VERSION "Nissan Leaf 2025 capstone DBC - original names plus verified gear observations"

NS_ :

BS_:
BU_: XXX

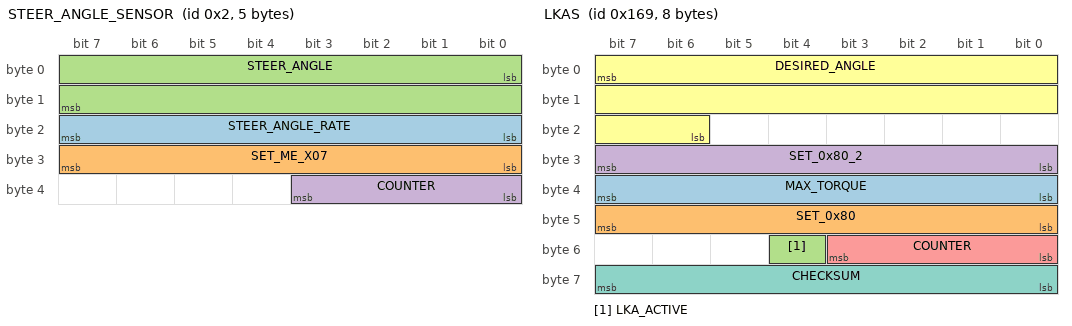
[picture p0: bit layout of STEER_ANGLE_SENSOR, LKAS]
BO_ 2 STEER_ANGLE_SENSOR: 5 XXX
 SG_ STEER_ANGLE_RATE : 16|8@1+ (1,0) [0|255] "" XXX
 SG_ SET_ME_X07 : 24|8@1+ (1,0) [0|255] "" XXX
 SG_ STEER_ANGLE : 0|16@1- (-0.1,0) [-3276.7|3276.8] "deg" XXX
 SG_ COUNTER : 32|4@1+ (1,0) [0|15] "" XXX

BO_ 42 SEATBELT: 8 XXX
 SG_ SEATBELT_DRIVER_LATCHED : 27|1@1+ (1,0) [0|1] "" XXX
 SG_ SEATBELT_DRIVER_UNLATCHED : 26|1@0+ (1,0) [0|1] "" XXX

BO_ 361 LKAS: 8 XXX
 SG_ MAX_TORQUE : 39|8@0+ (0.01,0) [0|2.55] "Nm" XXX
 SG_ SET_0x80 : 47|8@0+ (1,0) [0|255] "" XXX
 SG_ LKA_ACTIVE : 52|1@0+ (1,0) [0|1] "" XXX
 SG_ SET_0x80_2 : 31|8@0+ (1,0) [0|255] "" XXX
 SG_ COUNTER : 51|4@0+ (1,0) [0|15] "" XXX
 SG_ DESIRED_ANGLE : 7|18@0+ (-0.01,1310) [-1311.43|1310] "deg" XXX
 SG_ CHECKSUM : 63|8@0+ (1,0) [0|255] "" XXX

BO_ 372 GEAR_POSITION_STATUS: 8 XXX
 SG_ GEAR_POSITION : 24|8@1+ (1,0) [0|255] "" XXX
 SG_ GEAR_COUNTER : 32|4@1+ (1,0) [0|15] "" XXX

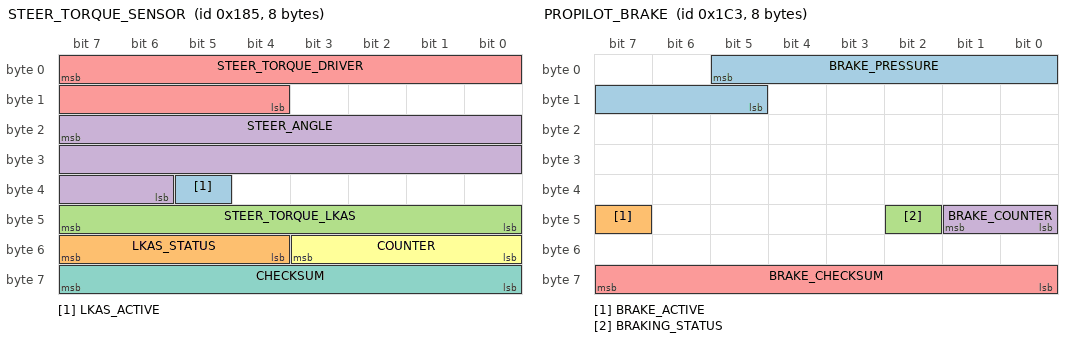
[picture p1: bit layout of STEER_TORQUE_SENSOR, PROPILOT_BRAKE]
BO_ 389 STEER_TORQUE_SENSOR: 8 XXX
 SG_ LKAS_ACTIVE : 37|1@0+ (1,0) [0|1] "" XXX
 SG_ LKAS_STATUS : 55|4@0+ (1,0) [0|15] "" XXX
 SG_ STEER_TORQUE_LKAS : 47|8@0+ (1,0) [0|255] "" XXX
 SG_ STEER_ANGLE : 23|18@0+ (-0.01,1310) [-1311.43|1310] "deg" XXX
 SG_ STEER_TORQUE_DRIVER : 7|12@0+ (-0.01,20.47) [-20.48|20.47] "Nm" XXX
 SG_ COUNTER : 51|4@0+ (1,0) [0|15] "" XXX
 SG_ CHECKSUM : 63|8@0+ (1,0) [0|255] "" XXX

BO_ 451 PROPILOT_BRAKE: 8 XXX
 SG_ BRAKE_PRESSURE : 5|9@0+ (1,0) [0|511] "" XXX
 SG_ BRAKE_ACTIVE : 47|1@0+ (1,0) [0|1] "" XXX
 SG_ BRAKING_STATUS : 42|1@1+ (1,0) [0|1] "" XXX
 SG_ BRAKE_COUNTER : 40|2@1+ (1,0) [0|3] "" XXX
 SG_ BRAKE_CHECKSUM : 56|8@1+ (1,0) [0|255] "" XXX

BO_ 459 BRAKE_RELATED_1CB: 7 XXX
 SG_ BRAKE_RELATED_STATUS : 13|1@1+ (1,0) [0|1] "" XXX
 SG_ BRAKE_RELATED_VALUE : 16|8@1+ (1,0) [0|255] "" XXX

BO_ 460 BRAKE_PEDAL: 4 XXX
 SG_ BRAKE_PEDAL : 7|8@0+ (1,0) [0|255] "" XXX

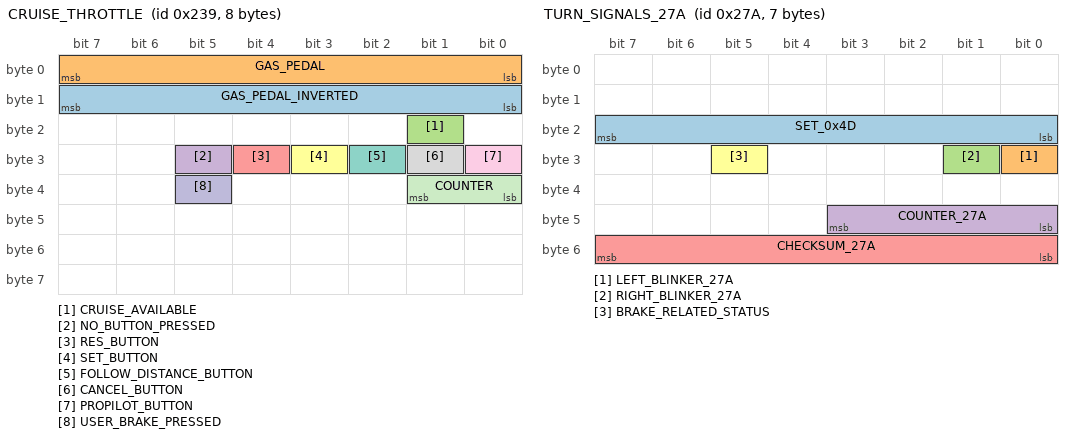
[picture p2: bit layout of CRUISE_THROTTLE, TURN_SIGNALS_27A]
BO_ 569 CRUISE_THROTTLE: 8 XXX
 SG_ GAS_PEDAL_INVERTED : 15|8@0+ (1,0) [0|255] "" XXX
 SG_ GAS_PEDAL : 7|8@0+ (1,0) [0|255] "" XXX
 SG_ CRUISE_AVAILABLE : 17|1@0+ (1,0) [0|1] "" XXX
 SG_ NO_BUTTON_PRESSED : 29|1@0+ (1,0) [0|1] "" XXX
 SG_ RES_BUTTON : 28|1@0+ (1,0) [0|1] "" XXX
 SG_ SET_BUTTON : 27|1@0+ (1,0) [0|1] "" XXX
 SG_ FOLLOW_DISTANCE_BUTTON : 26|1@0+ (1,0) [0|1] "" XXX
 SG_ CANCEL_BUTTON : 25|1@0+ (1,0) [0|1] "" XXX
 SG_ PROPILOT_BUTTON : 24|1@0+ (1,0) [0|1] "" XXX
 SG_ USER_BRAKE_PRESSED : 37|1@0+ (1,0) [0|1] "" XXX
 SG_ COUNTER : 32|2@1+ (1,0) [0|3] "" XXX

BO_ 634 TURN_SIGNALS_27A: 7 XXX
 SG_ SET_0x4D : 23|8@0+ (1,0) [0|255] "" XXX
 SG_ LEFT_BLINKER_27A : 24|1@1+ (1,0) [0|1] "" XXX
 SG_ RIGHT_BLINKER_27A : 25|1@1+ (1,0) [0|1] "" XXX
 SG_ COUNTER_27A : 40|4@1+ (1,0) [0|15] "" XXX
 SG_ CHECKSUM_27A : 48|8@1+ (1,0) [0|255] "" XXX
 SG_ BRAKE_RELATED_STATUS : 29|1@1+ (1,0) [0|1] "" XXX

BO_ 640 CANCEL_MSG: 8 XXX
 SG_ CANCEL_SEATBELT : 1|1@0+ (1,0) [0|1] "" XXX

BO_ 644 WHEEL_SPEEDS_FRONT: 8 XXX
 SG_ WHEEL_SPEED_FR : 7|16@0+ (0.005,0) [0|327.675] "KPH" XXX
 SG_ WHEEL_SPEED_FL : 23|16@0+ (0.005,0) [0|327.675] "KPH" XXX

BO_ 645 WHEEL_SPEEDS_REAR: 8 XXX
 SG_ WHEEL_SPEED_RR : 7|16@0+ (0.005,0) [0|327.675] "KPH" XXX
 SG_ WHEEL_SPEED_RL : 23|16@0+ (0.005,0) [0|327.675] "KPH" XXX

BO_ 654 BRAKE_RELATED_28E: 6 XXX
 SG_ AUTO_BRAKING_STATUS : 16|1@1+ (1,0) [0|1] "" XXX

BO_ 658 ACCEL: 8 XXX
 SG_ ROUGH_ACCEL : 7|16@0+ (0.0005,-16.5) [-16.5|16.27] "m/s^2" XXX

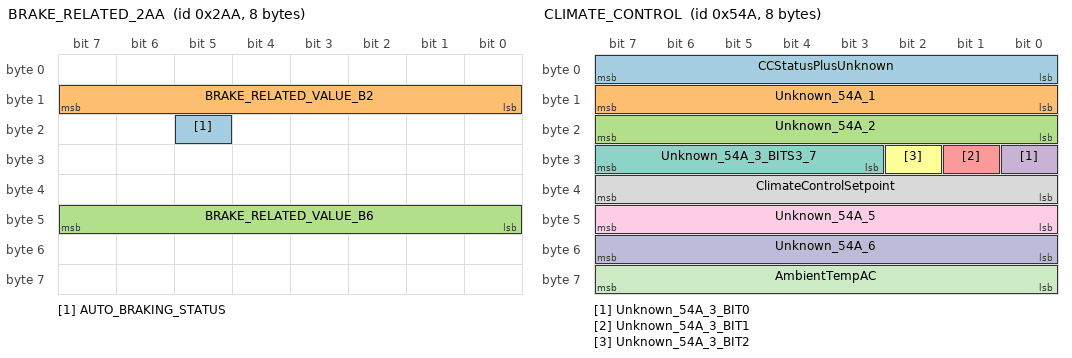
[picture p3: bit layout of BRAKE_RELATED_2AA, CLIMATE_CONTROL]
BO_ 682 BRAKE_RELATED_2AA: 8 XXX
 SG_ AUTO_BRAKING_STATUS : 21|1@1+ (1,0) [0|1] "" XXX
 SG_ BRAKE_RELATED_VALUE_B2 : 8|8@1+ (1,0) [0|255] "" XXX
 SG_ BRAKE_RELATED_VALUE_B6 : 40|8@1+ (1,0) [0|255] "" XXX

BO_ 688 BRAKE_RELATED_2B0: 8 XXX
 SG_ AUTO_BRAKING_STATUS : 22|1@1+ (1,0) [0|1] "" XXX

BO_ 689 PROPILOT_HUD: 8 XXX
 SG_ LARGE_WARNING_FLASHING : 9|1@0+ (1,0) [0|1] "" XXX
 SG_ SIDE_RADAR_ERROR_FLASHING1 : 10|1@0+ (1,0) [0|1] "" XXX
 SG_ SIDE_RADAR_ERROR_FLASHING2 : 11|1@0+ (1,0) [0|1] "" XXX
 SG_ RIGHT_LANE_YELLOW_FLASH : 12|1@0+ (1,0) [0|1] "" XXX
 SG_ LEFT_LANE_YELLOW_FLASH : 13|1@0+ (1,0) [0|1] "" XXX
 SG_ LEAD_CAR : 14|1@0+ (1,0) [0|1] "" XXX
 SG_ LEAD_CAR_ERROR : 15|1@0+ (1,0) [0|1] "" XXX
 SG_ FRONT_RADAR_ERROR : 16|1@0+ (1,0) [0|1] "" XXX
 SG_ FRONT_RADAR_ERROR_FLASHING : 17|1@0+ (1,0) [0|1] "" XXX
 SG_ RIGHT_LANE_GREEN : 24|1@0+ (1,0) [0|1] "" XXX
 SG_ LEFT_LANE_GREEN : 25|1@0+ (1,0) [0|1] "" XXX
 SG_ SIDE_RADAR_ERROR_FLASHING3 : 27|1@0+ (1,0) [0|1] "" XXX
 SG_ LKAS_ERROR_FLASHING : 29|1@0+ (1,0) [0|1] "" XXX
 SG_ SAFETY_SHIELD_ACTIVE : 44|1@0+ (1,0) [0|1] "" XXX
 SG_ LARGE_STEERING_WHEEL_ICON : 61|2@0+ (1,0) [0|3] "" XXX
 SG_ RIGHT_LANE_GREEN_FLASH : 62|1@0+ (1,0) [0|1] "" XXX
 SG_ LEFT_LANE_GREEN_FLASH : 63|1@0+ (1,0) [0|1] "" XXX
 SG_ FOLLOW_DISTANCE : 3|2@0+ (1,0) [0|3] "" XXX
 SG_ AUDIBLE_TONE : 47|3@0+ (1,0) [0|7] "" XXX
 SG_ SPEED_SET_ICON : 7|2@0+ (1,0) [0|3] "" XXX
 SG_ SMALL_STEERING_WHEEL_ICON : 42|3@0+ (1,0) [0|7] "" XXX
 SG_ SET_SPEED : 39|8@0+ (1,0) [0|255] "" XXX

BO_ 761 BRAKE_RELATED_2F9: 2 XXX
 SG_ AUTO_BRAKING_STATUS_INVERTED : 6|1@1+ (1,0) [0|1] "" XXX

BO_ 783 CRUISE_STATE: 3 XXX
 SG_ CRUISE_ENABLED : 3|1@0+ (1,0) [0|1] "" XXX

BO_ 852 ESP: 8 XXX
 SG_ ESP_DISABLED : 38|1@0+ (1,0) [0|1] "" XXX
 SG_ BRAKE_RELATED_STATUS : 52|1@1+ (1,0) [0|1] "" XXX

BO_ 853 HUD_SETTINGS: 8 XXX
 SG_ SPEED_MPH : 37|1@0+ (1,0) [0|1] "" XXX

BO_ 856 LIGHTS: 8 XXX
 SG_ LEFT_BLINKER : 17|1@0+ (1,0) [0|1] "" XXX
 SG_ RIGHT_BLINKER : 18|1@0+ (1,0) [0|1] "" XXX

BO_ 861 BRAKE_RELATED_35D: 8 XXX
 SG_ BRAKE_RELATED_STATUS : 36|1@1+ (1,0) [0|1] "" XXX

BO_ 943 HAZARD_SWITCH: 8 XXX
 SG_ HAZARD_BUTTON : 7|1@1+ (1,0) [0|1] "" XXX

BO_ 976 GEAR_SYSTEM_STATUS: 6 XXX
 SG_ GEAR_STATE : 8|8@1+ (1,0) [0|255] "" XXX
 SG_ GEAR_COUNTER : 40|2@1+ (1,0) [0|3] "" XXX

BO_ 1057 GEARBOX: 3 XXX
 SG_ GEAR_SHIFTER : 5|3@0+ (1,0) [0|7] "" XXX

BO_ 1227 LKAS_SETTINGS: 8 XXX
 SG_ LKAS_ENABLED : 51|1@0+ (1,0) [0|1] "" XXX

BO_ 1228 PROPILOT_HUD_INFO_MSG: 8 XXX
 SG_ NA_HIGH_ACCEL_TEMP : 0|1@0+ (1,0) [0|1] "" XXX
 SG_ SIDE_RADAR_NA_HIGH_CABIN_TEMP : 8|1@0+ (1,0) [0|1] "" XXX
 SG_ SIDE_RADAR_MALFUNCTION : 11|1@0+ (1,0) [0|1] "" XXX
 SG_ LKAS_MALFUNCTION : 12|1@0+ (1,0) [0|1] "" XXX
 SG_ FRONT_RADAR_MALFUNCTION : 13|1@0+ (1,0) [0|1] "" XXX
 SG_ SIDE_RADAR_NA_CLEAN_REAR_CAMERA : 14|1@0+ (1,0) [0|1] "" XXX
 SG_ NA_POOR_ROAD_CONDITIONS : 16|1@0+ (1,0) [0|1] "" XXX
 SG_ CURRENTLY_UNAVAILABLE : 17|1@0+ (1,0) [0|1] "" XXX
 SG_ SAFETY_SHIELD_OFF : 18|1@0+ (1,0) [0|1] "" XXX
 SG_ FRONT_COLLISION_NA_FRONT_RADAR_OBSTRUCTION : 20|1@0+ (1,0) [0|1] "" XXX
 SG_ PEDAL_MISSAPPLICATION_SYSTEM_ACTIVATED : 24|1@0+ (1,0) [0|1] "" XXX
 SG_ SIDE_IMPACT_NA_RADAR_OBSTRUCTION : 25|1@0+ (1,0) [0|1] "" XXX
 SG_ WARNING_DO_NOT_ENTER : 33|1@0+ (1,0) [0|1] "" XXX
 SG_ SIDE_IMPACT_SYSTEM_OFF : 34|1@0+ (1,0) [0|1] "" XXX
 SG_ SIDE_IMPACT_MALFUNCTION : 35|1@0+ (1,0) [0|1] "" XXX
 SG_ FRONT_COLLISION_MALFUNCTION : 36|1@0+ (1,0) [0|1] "" XXX
 SG_ SIDE_RADAR_MALFUNCTION2 : 37|1@0+ (1,0) [0|1] "" XXX
 SG_ LKAS_MALFUNCTION2 : 38|1@0+ (1,0) [0|1] "" XXX
 SG_ FRONT_RADAR_MALFUNCTION2 : 39|1@0+ (1,0) [0|1] "" XXX
 SG_ PROPILOT_NA_MSGS : 42|3@0+ (1,0) [0|7] "" XXX
 SG_ BOTTOM_MSG : 45|3@0+ (1,0) [0|7] "" XXX
 SG_ HANDS_ON_WHEEL_WARNING : 47|1@0+ (1,0) [0|1] "" XXX
 SG_ WARNING_STEP_ON_BRAKE_NOW : 51|1@0+ (1,0) [0|1] "" XXX
 SG_ PROPILOT_NA_FRONT_CAMERA_OBSTRUCTED : 52|1@0+ (1,0) [0|1] "" XXX
 SG_ PROPILOT_NA_HIGH_CABIN_TEMP : 53|1@0+ (1,0) [0|1] "" XXX
 SG_ WARNING_PROPILOT_MALFUNCTION : 54|1@0+ (1,0) [0|1] "" XXX
 SG_ ACC_UNAVAILABLE_HIGH_CABIN_TEMP : 62|1@0+ (1,0) [0|1] "" XXX
 SG_ ACC_NA_FRONT_CAMERA_IMPARED : 63|1@0+ (1,0) [0|1] "" XXX

BO_ 1354 CLIMATE_CONTROL: 8 XXX
 SG_ CCStatusPlusUnknown : 0|8@1+ (1,0) [0|255] "" XXX
 SG_ Unknown_54A_1 : 8|8@1+ (1,0) [0|255] "" XXX
 SG_ Unknown_54A_2 : 16|8@1+ (1,0) [0|255] "" XXX
 SG_ Unknown_54A_3_BIT0 : 24|1@1+ (1,0) [0|1] "" XXX
 SG_ Unknown_54A_3_BIT1 : 25|1@1+ (1,0) [0|1] "" XXX
 SG_ Unknown_54A_3_BIT2 : 26|1@1+ (1,0) [0|1] "" XXX
 SG_ Unknown_54A_3_BITS3_7 : 27|5@1+ (1,0) [0|31] "" XXX
 SG_ ClimateControlSetpoint : 32|8@1+ (1,0) [0|255] "" XXX
 SG_ Unknown_54A_5 : 40|8@1+ (1,0) [0|255] "" XXX
 SG_ Unknown_54A_6 : 48|8@1+ (1,0) [0|255] "" XXX
 SG_ AmbientTempAC : 56|8@1+ (1,0) [0|255] "" XXX

BO_ 1402 REVERSE_STATUS: 8 XXX
 SG_ REVERSE_RELATED_STATE : 0|8@1+ (1,0) [0|255] "" XXX

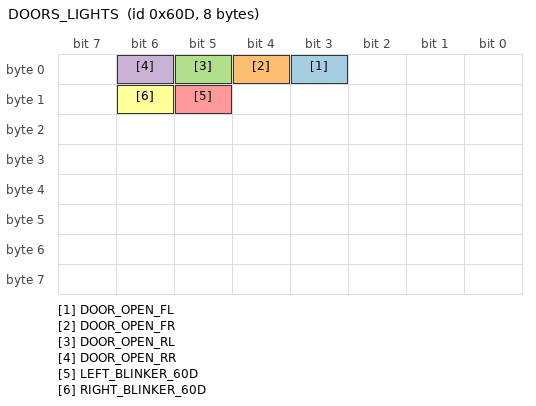
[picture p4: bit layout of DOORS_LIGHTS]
BO_ 1549 DOORS_LIGHTS: 8 XXX
 SG_ DOOR_OPEN_FL : 3|1@0+ (1,0) [0|1] "" XXX
 SG_ DOOR_OPEN_FR : 4|1@0+ (1,0) [0|1] "" XXX
 SG_ DOOR_OPEN_RL : 5|1@0+ (1,0) [0|1] "" XXX
 SG_ DOOR_OPEN_RR : 6|1@0+ (1,0) [0|1] "" XXX
 SG_ LEFT_BLINKER_60D : 13|1@1+ (1,0) [0|1] "" XXX
 SG_ RIGHT_BLINKER_60D : 14|1@1+ (1,0) [0|1] "" XXX

CM_ SG_ 389 LKAS_STATUS "EPS LKAS state.";
VAL_ 389 LKAS_STATUS 5 "INACTIVE" 6 "ACTIVE" 9 "FAULT" ;
VAL_ 1057 GEAR_SHIFTER 7 "B" 4 "D" 3 "N" 2 "R" 1 "P" ;
VAL_ 1228 PROPILOT_NA_MSGS 0 "NO_MSG" 1 "NA_FRONT_CAMERA_IMPAIRED" 2 "STEERING_ASSIST_ON_STANDBY" 3 "NA_PARKING_ASSIST_ENABLED" 4 "STEER_ASSIST_CURRENTLY_NA" 5 "NA_BAD_WEATHER" 6 "NA_PARK_BRAKE_ON" 7 "NA_SEATBELT_NOT_FASTENED" ;
VAL_ 1228 BOTTOM_MSG 0 "OK_STEER_ASSIST_SETTINGS" 1 "NO_MSG" 2 "PRESS_SET_TO_SET_SPEED" 3 "PRESS_RES_SET_TO_CHANGE_SPEED" 4 "PRESS_RES_TO_RESTART" 5 "NO_MSG" 6 "CRUISE_NOT_AVAIL" 7 "NO_MSG" ;
VAL_ 689 FOLLOW_DISTANCE 0 "NO_FOLLOW_DISTANCE" 1 "FOLLOW_DISTANCE_1" 2 "FOLLOW_DISTANCE_2" 3 "FOLLOW_DISTANCE_3" ;
VAL_ 689 AUDIBLE_TONE 0 "NO_TONE" 1 "CONT" 2 "FAST_BEEP_CONT" 3 "TRIPLE_FAST_BEEP_CONT" 4 "SLOW_BEEP_CONT" 5 "QUAD_SLOW_BEEP_CONT" 6 "SINGLE_BEEP_ONCE" 7 "DOUBLE_BEEP_ONCE" ;
VAL_ 689 SMALL_STEERING_WHEEL_ICON 0 "NO_ICON" 1 "GRAY_ICON" 2 "GRAY_ICON_FLASHING" 3 "GREEN_ICON" 4 "GREEN_ICON_FLASHING" 5 "RED_ICON" 6 "RED_ICON_FLASHING" 7 "YELLOW_ICON" ;
VAL_ 689 LARGE_STEERING_WHEEL_ICON 0 "NO_STEERINGWHEEL" 1 "GRAY_STEERINGWHEEL" 2 "GREEN_STEERINGWHEEL" 3 "GREEN_STEERINGWHEEL_FLASHING" ;

VAL_ 372 GEAR_POSITION 170 "PARK" 153 "REVERSE" 187 "DRIVE" ;
VAL_ 976 GEAR_STATE 131 "PARK_OBSERVED" 133 "REVERSE_ENTRY_OBSERVED" 197 "REVERSE_SUSTAINED_OBSERVED" 137 "DRIVE_OBSERVED" 129 "TRANSITION_OBSERVED" ;
VAL_ 1402 REVERSE_RELATED_STATE 8 "NORMAL_OBSERVED" 200 "REVERSE_ASSOCIATED_OBSERVED" ;

CM_ BO_ 2 "Steering angle sensor. Our testing confirmed steering-angle behavior, steering-rate behavior, fixed 0x07 field, approximately 100 Hz transmission, and 4-bit rolling counter.";
CM_ BO_ 361 "Nissan LKAS steering-control message. NOT seen in any of our captures - we have not confirmed this car transmits it, or on which bus. LKAS_BUS in manual_nissancan.py is a placeholder until we capture it.";
CM_ BO_ 634 "Observed turn-signal state message. Captured on BUS 2 at 47.5 Hz over 50432 frames. REPORTS lamp state rather than commanding it: byte 4 toggles with the physical flash at about 1.43 Hz, and every sustained hazard period begins 20-30 ms AFTER a 0x3AF pulse. Transmitting this message is not expected to command the lamps.";
CM_ SG_ 634 SET_0x4D "Constant 0x4D across all 50432 captured frames. Observed on received frames; not validated for transmission.";
CM_ SG_ 634 COUNTER_27A "Confirmed 4-bit rolling counter in byte 6 low nibble. Sequence 0 through 15 then wraps to 0.";
CM_ SG_ 634 CHECKSUM_27A "Confirmed additive checksum. Checksum = (Byte1 + Byte2 + Byte3 + Byte4 + Byte5 + Byte6 + 0x7C) & 0xFF.";
CM_ BO_ 943 "Observed hazard-switch press message. Captured on BUS 0 at 10.1 Hz; bytes 2-8 constant 0x00, no counter and no checksum. 110 pulses observed, width 0.131 s min / 0.250 s median / 0.560 s max, so a press is roughly 2-3 frames at 10 Hz. This is a hazard switch input indication; all 35 sustained hazard periods in 0x27A began 20-30 ms after a pulse here.";
CM_ BO_ 1549 "Door-status message also contains turn-signal state. Captured on BUS 0 at 10.3 Hz. Byte 2 toggles 0x06 <-> 0x66 in lockstep with the 0x27A flash, which confirms bits 5 and 6 as the two blinker lamps. Like 0x27A this message REPORTS lamp state.";

CM_ BO_ 451 "Factory ProPILOT braking associated with this message in 2025 Leaf road test. Existing BRAKE_PRESSURE and BRAKE_ACTIVE names preserved. Control request versus feedback unknown. Decode only.";
CM_ SG_ 451 BRAKE_PRESSURE "Raw magnitude 0-364 observed, not calibrated to pressure units. Original name preserved.";
CM_ SG_ 451 BRAKE_ACTIVE "Observed during automatic braking. Cannot infer this bit actuates brakes.";
CM_ SG_ 451 BRAKING_STATUS "Additional braking-related status observed at Byte 6 bit 2; detailed meaning unknown.";
CM_ SG_ 451 BRAKE_COUNTER "Byte 6 bits 0-1, observed cycling 0,1,2,3.";
CM_ SG_ 451 BRAKE_CHECKSUM "Byte 8 additive integrity relation confirmed in 263475 captured frames; receive-side only.";
CM_ BO_ 460 "Original BRAKE_PEDAL name retained. Actual captured message length 4 bytes, not 8. Its magnitude changes during automatic braking too, so does not exclusively indicate driver pedal input.";
CM_ BO_ 459 "Additional candidate received message 0x1CB. Status correlated with automatic braking; raw value associated with manual braking. Exact meanings unverified.";
CM_ SG_ 459 BRAKE_RELATED_STATUS "Byte 2 bit 5; active in 81.8 percent of braking intervals vs 4.5 percent inactive intervals in sampled comparison. Not an actuation command.";
CM_ SG_ 459 BRAKE_RELATED_VALUE "Byte 3 raw value; associated with manual brake testing, units and function unknown.";
CM_ BO_ 654 "Additional status candidate 0x28E; observed on Panda bus 1; association with factory braking, not a verified command.";
CM_ BO_ 682 "Additional brake-related message 0x2AA. Correlated with factory braking, exact field definitions and ECU source unverified.";
CM_ BO_ 688 "Additional status candidate 0x2B0 observed on Panda bus 1 during factory braking.";
CM_ BO_ 761 "Additional status candidate 0x2F9. Its observed bit mostly clears while factory braking is active; not a verified brake command.";
CM_ BO_ 861 "Message 0x35D contains a status candidate correlated with manual brake input; exact function unverified.";
CM_ SG_ 634 BRAKE_RELATED_STATUS "Observed correlation with brake-pedal activity at Byte 4 bit 5. This message also reports turn signal state; does not control brakes.";
CM_ SG_ 852 BRAKE_RELATED_STATUS "Observed correlation with manual brake input; exact meaning unverified.";
CM_ SG_ 861 BRAKE_RELATED_STATUS "Observed correlation with manual brake input; exact meaning unverified.";
CM_ BO_ 1354 "HVAC message 0x54A recorded on buses 0 and 2 at around 10Hz. Names mostly preserved from ZE1 DBC. No conventional rolling counter or payload checksum confirmed. Receive-side only.";
CM_ SG_ 1354 CCStatusPlusUnknown "Byte 1 alternates 0x3C and 0xDA, exact purpose not established.";
CM_ SG_ 1354 Unknown_54A_3_BIT0 "Byte 4 bit 0 changes during HVAC operation, purpose unverified.";
CM_ SG_ 1354 Unknown_54A_3_BIT2 "Byte 4 bit 2, inverted HVAC ON/OFF association: 0 observed during ON, 1 during OFF. This is NOT verified as AC compressor power.";
CM_ SG_ 1354 ClimateControlSetpoint "Byte 5 increments with selected temperature changes: observed raw 78-84, 0 when inactive. Exact display scaling not independently confirmed.";
CM_ SG_ 1354 AmbientTempAC "Original ZE1 name retained; byte 8 constant 0x6D in newer recording; physical scaling not verified.";

CM_ BO_ 372 "Observed gear-position status on Panda buses 0 and 2, DLC 8 at approx 100 Hz, during stationary P/R/D shifting. Receive-side observation; no command behavior verified.";
CM_ SG_ 372 GEAR_POSITION "Byte 4 complete code: 0xAA Park, 0x99 Reverse, 0xBB Drive. Correlated with driver's gear-selection sequence; this is not evidence of an accepted shift request.";
CM_ SG_ 372 GEAR_COUNTER "Byte 5 lower nibble cycles 0..15; one discontinuity among 28334 consecutive captured bus-0 transitions. Other bits not decoded.";
CM_ BO_ 976 "Observed gear-system status on Panda buses 0 and 2, DLC 6 at approx 50 Hz. Byte 2 encodes gear-correlated states, including a delayed secondary Reverse state. Receive-side only.";
CM_ SG_ 976 GEAR_STATE "Observed Byte 2: 0x83 Park, 0x85 initial Reverse, 0xC5 sustained Reverse, 0x89 Drive, 0x81 transition. These are correlations, not verified shift commands.";
CM_ SG_ 976 GEAR_COUNTER "Byte 6 bits 0-1 cycle modulo 4, with some discontinuities. Remaining bits of Byte 6 are not established as a checksum.";
CM_ BO_ 1402 "Observed reverse-associated status on Panda buses 0 and 2, DLC 8 at approx 10 Hz. Changes after Reverse selection. Not a confirmed shifter request, reversing-light or camera control.";
CM_ SG_ 1402 REVERSE_RELATED_STATE "Byte 1 usually 0x08 outside Reverse and 0xC8 during Reverse; rare transitional values 0x48 and 0x88 also observed. Exact function not confirmed.";
